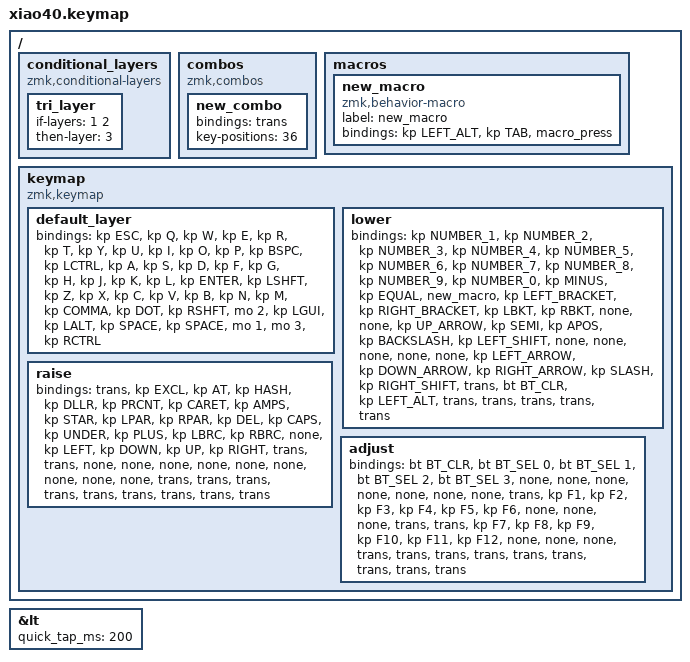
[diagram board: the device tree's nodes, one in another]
/*
 * Copyright (c) 2022 Ramon Imbao
 *
 * SPDX-License-Identifier: MIT
 */

#include <behaviors.dtsi>
#include <dt-bindings/zmk/keys.h>
#include <dt-bindings/zmk/bt.h>

&lt {
    quick_tap_ms = <200>;
};

/ {
    conditional_layers {
        compatible = "zmk,conditional-layers";

        tri_layer {
            if-layers = <1 2>;
            then-layer = <3>;
        };
    };

    combos {
        compatible = "zmk,combos";

        new_combo {
            bindings = <&trans>;
            key-positions = <36>;
        };
    };

    macros {
        new_macro: new_macro {
            compatible = "zmk,behavior-macro";
            label = "new_macro";
            #binding-cells = <0>;
            bindings =
                <&kp LEFT_ALT &kp TAB>,
                <&macro_press>;
        };
    };

    keymap {
        compatible = "zmk,keymap";

        default_layer {
            bindings = <
 &kp ESC   &kp Q   &kp W   &kp E   &kp R   &kp T   &kp Y   &kp U   &kp I   &kp O   &kp P  &kp BSPC  &kp LCTRL   &kp A   &kp S   &kp D   &kp F   &kp G   &kp H   &kp J   &kp K   &kp L  &kp ENTER  &kp LSHFT   &kp Z   &kp X   &kp C   &kp V   &kp B   &kp N   &kp M  &kp COMMA  &kp DOT  &kp RSHFT   &mo 2  &kp LGUI  &kp LALT  &kp SPACE  &kp SPACE   &mo 1   &mo 3  &kp RCTRL
            >;
        };

        lower {
            bindings = <
 &kp NUMBER_1  &kp NUMBER_2  &kp NUMBER_3  &kp NUMBER_4  &kp NUMBER_5  &kp NUMBER_6  &kp NUMBER_7  &kp NUMBER_8  &kp NUMBER_9  &kp NUMBER_0  &kp MINUS  &kp EQUAL  &new_macro  &kp LEFT_BRACKET  &kp RIGHT_BRACKET  &kp LBKT  &kp RBKT   &none   &none  &kp UP_ARROW  &kp SEMI  &kp APOS  &kp BACKSLASH  &kp LEFT_SHIFT   &none   &none   &none   &none   &none  &kp LEFT_ARROW  &kp DOWN_ARROW  &kp RIGHT_ARROW  &kp SLASH  &kp RIGHT_SHIFT  &trans  &bt BT_CLR  &kp LEFT_ALT  &trans  &trans  &trans  &trans  &trans
            >;
        };

        raise {
            bindings = <
 &trans  &kp EXCL  &kp AT  &kp HASH  &kp DLLR  &kp PRCNT  &kp CARET  &kp AMPS  &kp STAR  &kp LPAR  &kp RPAR  &kp DEL  &kp CAPS  &kp UNDER  &kp PLUS  &kp LBRC  &kp RBRC   &none  &kp LEFT  &kp DOWN  &kp UP  &kp RIGHT  &trans  &trans   &none   &none   &none   &none   &none   &none   &none   &none   &none  &trans  &trans  &trans  &trans  &trans  &trans  &trans  &trans  &trans
            >;
        };

        adjust {
            bindings = <
 &bt BT_CLR  &bt BT_SEL 0  &bt BT_SEL 1  &bt BT_SEL 2  &bt BT_SEL 3   &none   &none   &none   &none   &none   &none   &none  &trans  &kp F1  &kp F2  &kp F3  &kp F4  &kp F5  &kp F6   &none   &none   &none  &trans  &trans  &kp F7  &kp F8  &kp F9  &kp F10  &kp F11  &kp F12   &none   &none   &none  &trans  &trans  &trans  &trans  &trans  &trans  &trans  &trans  &trans
            >;
        };
    };
};
